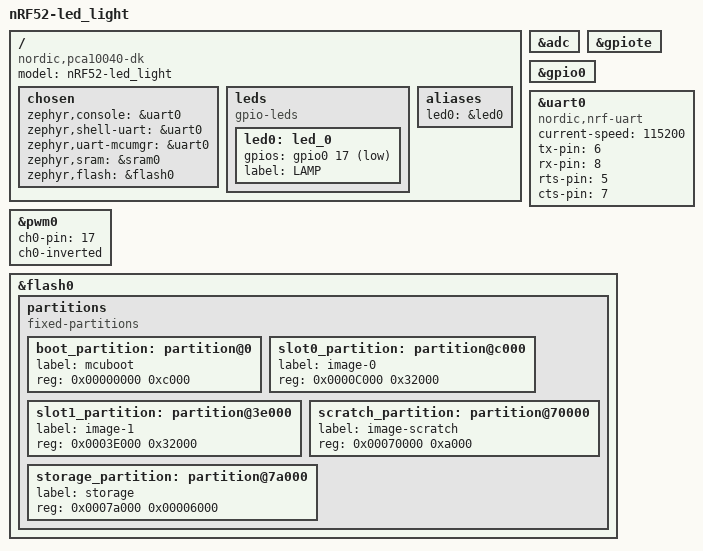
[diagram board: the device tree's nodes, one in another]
/*
 * Copyright (c) 2017 Shawn Nock <shawn@monadnock.ca>
 * Copyright (c) 2017 Linaro Limited
 *
 * SPDX-License-Identifier: Apache-2.0
 */

/dts-v1/;
#include <nordic/nrf52832_qfaa.dtsi>

/ {
	model = "nRF52-led_light";
	compatible = "nordic,pca10040-dk", "nordic,nrf52832-qfaa",
		     "nordic,nrf52832";

	chosen {
		zephyr,console = &uart0;
		zephyr,shell-uart = &uart0;
		zephyr,uart-mcumgr = &uart0;
		zephyr,sram = &sram0;
		zephyr,flash = &flash0;
	};
    /* TODO: Change lamp pin to 8 */
	leds {
		compatible = "gpio-leds";
		led0: led_0 {
			gpios = <&gpio0 17 GPIO_INT_ACTIVE_LOW>;
			label = "LAMP";
		};
	};

	/* These aliases are provided for compatibility with samples */
	aliases {
		led0 = &led0;
	};
};

&adc {
	status ="ok";
};

&gpiote {
	status ="ok";
};

&gpio0 {
	status ="ok";
};

&uart0 {
	status = "ok";
	compatible = "nordic,nrf-uart";
	current-speed = <115200>;
	tx-pin = <6>;
	rx-pin = <8>;
	rts-pin = <5>;
	cts-pin = <7>;
};

&pwm0 {
	status = "ok";
	ch0-pin = <17>;
	ch0-inverted;
};

&flash0 {
	/*
	 * For more information, see:
	 * http://docs.zephyrproject.org/latest/devices/dts/flash_partitions.html
	 */
	partitions {
		compatible = "fixed-partitions";
		#address-cells = <1>;
		#size-cells = <1>;

		boot_partition: partition@0 {
			label = "mcuboot";
			reg = <0x00000000 0xc000>;
		};
		slot0_partition: partition@c000 {
			label = "image-0";
			reg = <0x0000C000 0x32000>;
		};
		slot1_partition: partition@3e000 {
			label = "image-1";
			reg = <0x0003E000 0x32000>;
		};
		scratch_partition: partition@70000 {
			label = "image-scratch";
			reg = <0x00070000 0xa000>;
		};
		storage_partition: partition@7a000 {
			label = "storage";
			reg = <0x0007a000 0x00006000>;
		};
	};
};
